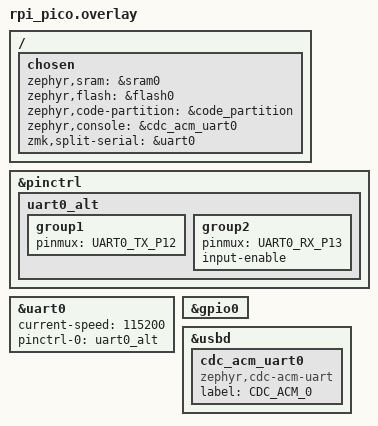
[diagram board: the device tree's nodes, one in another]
/ {
    chosen {
		zephyr,sram = &sram0;
		zephyr,flash = &flash0;
		zephyr,code-partition = &code_partition;
		zephyr,console = &cdc_acm_uart0;
        zmk,split-serial = &uart0;
    };
};

&pinctrl {
	uart0_alt: uart0_alt {
		group1 {
			pinmux = <UART0_TX_P12>;
		};
		group2 {
			pinmux = <UART0_RX_P13>;
			input-enable;
		};
	};
};

&uart0 {
	current-speed = <115200>;
	status = "okay";
	pinctrl-0 = <&uart0_alt>;
	pinctrl-names = "default";
};

&gpio0 {
	status = "okay";
};

zephyr_udc0: &usbd {
	status = "okay";
	cdc_acm_uart0: cdc_acm_uart0 {
		compatible = "zephyr,cdc-acm-uart";
		label = "CDC_ACM_0";
	};
};
